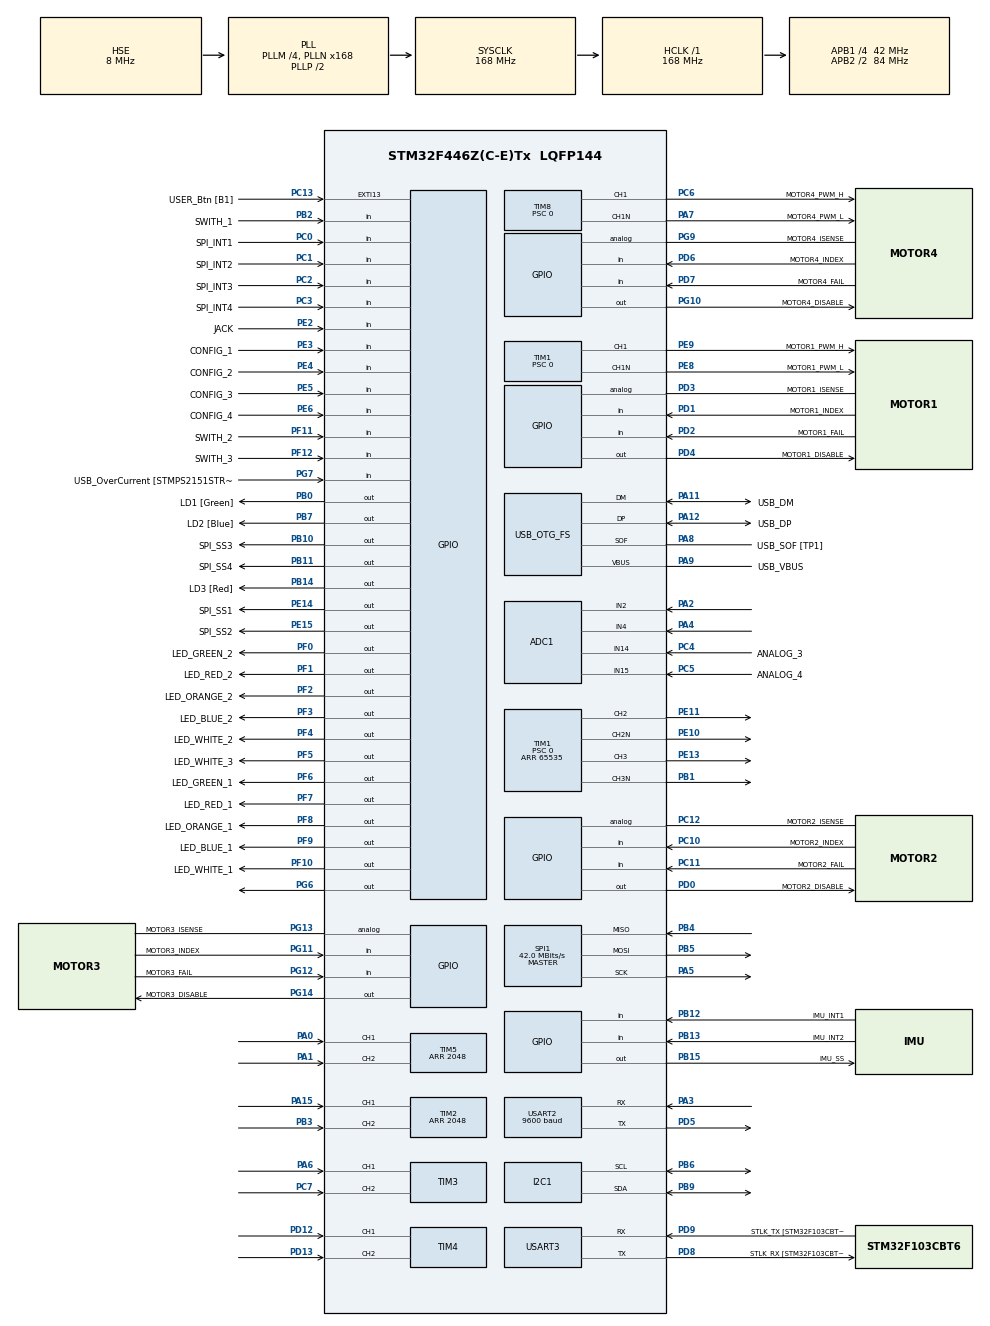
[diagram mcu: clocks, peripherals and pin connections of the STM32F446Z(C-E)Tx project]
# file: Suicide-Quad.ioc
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ADC1.Channel-2\#ChannelRegularConversion=ADC_CHANNEL_2
ADC1.NbrOfConversionFlag=1
ADC1.Rank-2\#ChannelRegularConversion=1
ADC1.SamplingTime-2\#ChannelRegularConversion=ADC_SAMPLETIME_3CYCLES
ADC1.master=1
Dma.Request0=USART2_TX
Dma.USART2_TX.0.Direction=DMA_MEMORY_TO_PERIPH
Dma.USART2_TX.0.FIFOMode=DMA_FIFOMODE_ENABLE
Dma.USART2_TX.0.FIFOThreshold=DMA_FIFO_THRESHOLD_FULL
Dma.USART2_TX.0.Instance=DMA1_Stream6
Dma.USART2_TX.0.MemBurst=DMA_MBURST_SINGLE
Dma.USART2_TX.0.MemDataAlignment=DMA_MDATAALIGN_BYTE
Dma.USART2_TX.0.MemInc=DMA_MINC_ENABLE
Dma.USART2_TX.0.Mode=DMA_CIRCULAR
Dma.USART2_TX.0.PeriphBurst=DMA_PBURST_SINGLE
Dma.USART2_TX.0.PeriphDataAlignment=DMA_PDATAALIGN_BYTE
Dma.USART2_TX.0.PeriphInc=DMA_PINC_DISABLE
Dma.USART2_TX.0.Priority=DMA_PRIORITY_LOW
Mcu.Family=STM32F4
Mcu.Name=STM32F446Z(C-E)Tx
Mcu.Package=LQFP144
NVIC.DMA1_Stream6_IRQn=true\:0\:0\:false\:false\:true\:false\:true\:true
NVIC.PriorityGroup=NVIC_PRIORITYGROUP_4
NVIC.TIM1_BRK_TIM9_IRQn=true\:0\:0\:false\:false\:true\:true\:true\:true
NVIC.USART2_IRQn=true\:0\:0\:false\:false\:true\:true\:true\:true
NVIC.USART3_IRQn=true\:0\:0\:false\:false\:true\:true\:true\:true
PA0-WKUP.Signal=S_TIM5_CH1
PA1.Signal=S_TIM5_CH2
PA10.GPIO_Label=USB_ID
PA10.Signal=USB_OTG_FS_ID
PA11.GPIO_Label=USB_DM
PA11.Mode=Device_Only
PA11.Signal=USB_OTG_FS_DM
PA12.GPIO_Label=USB_DP
PA12.Mode=Device_Only
PA12.Signal=USB_OTG_FS_DP
PA13.GPIO_Label=TMS
PA13.Mode=Serial_Wire
PA13.Signal=SYS_JTMS-SWDIO
PA14.GPIO_Label=TCK
PA14.Mode=Serial_Wire
PA14.Signal=SYS_JTCK-SWCLK
PA15.Signal=S_TIM2_CH1_ETR
PA2.Signal=ADCx_IN2
PA3.Mode=Asynchronous
PA3.Signal=USART2_RX
PA4.Signal=ADCx_IN4
PA5.Mode=Full_Duplex_Master
PA5.Signal=SPI1_SCK
PA6.Signal=S_TIM3_CH1
PA7.GPIO_Label=MOTOR4_PWM_L
PA7.Mode=PWM Generation1 CH1 CH1N
PA7.Signal=TIM8_CH1N
PA8.GPIO_Label=USB_SOF [TP1]
PA8.Mode=Activate_SOF_FS
PA8.Signal=USB_OTG_FS_SOF
PA9.GPIO_Label=USB_VBUS
PA9.Mode=Activate_VBUS
PA9.Signal=USB_OTG_FS_VBUS
PB0.GPIO_Label=LD1 [Green]
PB0.Signal=GPIO_Output
PB1.Mode=PWM Generation3 CH3 CH3N
PB1.Signal=TIM1_CH3N
PB10.GPIO_Label=SPI_SS3
PB10.Signal=GPIO_Output
PB11.GPIO_Label=SPI_SS4
PB11.Signal=GPIO_Output
PB12.GPIO_Label=IMU_INT1
PB12.Signal=GPIO_Input
PB13.GPIO_Label=IMU_INT2
PB13.Signal=GPIO_Input
PB14.GPIO_Label=LD3 [Red]
PB14.Signal=GPIO_Output
PB15.GPIO_Label=IMU_SS
PB15.Signal=GPIO_Output
PB2.GPIO_Label=SWITH_1
PB2.Signal=GPIO_Input
PB3.Signal=S_TIM2_CH2
PB4.Mode=Full_Duplex_Master
PB4.Signal=SPI1_MISO
PB5.Mode=Full_Duplex_Master
PB5.Signal=SPI1_MOSI
PB6.Mode=I2C
PB6.Signal=I2C1_SCL
PB7.GPIO_Label=LD2 [Blue]
PB7.Signal=GPIO_Output
PB9.Mode=I2C
PB9.Signal=I2C1_SDA
PC0.GPIO_Label=SPI_INT1
PC0.Signal=GPIO_Input
PC1.GPIO_Label=SPI_INT2
PC1.Signal=GPIO_Input
PC10.GPIO_Label=MOTOR2_INDEX
PC10.Signal=GPIO_Input
PC11.GPIO_Label=MOTOR2_FAIL
PC11.Signal=GPIO_Input
PC12.GPIO_Label=MOTOR2_ISENSE
PC12.Signal=GPIO_Analog
PC13.GPIO_Label=USER_Btn [B1]
PC13.Signal=GPXTI13
PC14-OSC32_IN.Mode=LSE-External-Oscillator
PC14-OSC32_IN.Signal=RCC_OSC32_IN
PC15-OSC32_OUT.Mode=LSE-External-Oscillator
PC15-OSC32_OUT.Signal=RCC_OSC32_OUT
PC2.GPIO_Label=SPI_INT3
PC2.Signal=GPIO_Input
PC3.GPIO_Label=SPI_INT4
PC3.Signal=GPIO_Input
PC4.GPIO_Label=ANALOG_3
PC4.Signal=ADCx_IN14
PC5.GPIO_Label=ANALOG_4
PC5.Signal=ADCx_IN15
PC6.GPIO_Label=MOTOR4_PWM_H
PC6.Signal=S_TIM8_CH1
PC7.Signal=S_TIM3_CH2
PD0.GPIO_Label=MOTOR2_DISABLE
PD0.Signal=GPIO_Output
PD1.GPIO_Label=MOTOR1_INDEX
PD1.Signal=GPIO_Input
PD12.Signal=S_TIM4_CH1
PD13.Signal=S_TIM4_CH2
PD2.GPIO_Label=MOTOR1_FAIL
PD2.Signal=GPIO_Input
PD3.GPIO_Label=MOTOR1_ISENSE
PD3.Signal=GPIO_Analog
PD4.GPIO_Label=MOTOR1_DISABLE
PD4.Signal=GPIO_Output
PD5.Mode=Asynchronous
PD5.Signal=USART2_TX
PD6.GPIO_Label=MOTOR4_INDEX
PD6.Signal=GPIO_Input
PD7.GPIO_Label=MOTOR4_FAIL
PD7.Signal=GPIO_Input
PD8.GPIO_Label=STLK_RX [STM32F103CBT6_PA3]
PD8.Mode=Asynchronous
PD8.Signal=USART3_TX
PD9.GPIO_Label=STLK_TX [STM32F103CBT6_PA2]
PD9.Mode=Asynchronous
PD9.Signal=USART3_RX
PE10.Mode=PWM Generation2 CH2 CH2N
PE10.Signal=TIM1_CH2N
PE11.Signal=S_TIM1_CH2
PE13.Signal=S_TIM1_CH3
PE14.GPIO_Label=SPI_SS1
PE14.Signal=GPIO_Output
PE15.GPIO_Label=SPI_SS2
PE15.Signal=GPIO_Output
PE2.GPIO_Label=JACK
PE2.Signal=GPIO_Input
PE3.GPIO_Label=CONFIG_1
PE3.Signal=GPIO_Input
PE4.GPIO_Label=CONFIG_2
PE4.Signal=GPIO_Input
PE5.GPIO_Label=CONFIG_3
PE5.Signal=GPIO_Input
PE6.GPIO_Label=CONFIG_4
PE6.Signal=GPIO_Input
PE8.GPIO_Label=MOTOR1_PWM_L
PE8.Mode=PWM Generation1 CH1 CH1N
PE8.Signal=TIM1_CH1N
PE9.GPIO_Label=MOTOR1_PWM_H
PE9.Signal=S_TIM1_CH1
PF0.GPIO_Label=LED_GREEN_2
PF0.Signal=GPIO_Output
PF1.GPIO_Label=LED_RED_2
PF1.Signal=GPIO_Output
PF10.GPIO_Label=LED_WHITE_1
PF10.Signal=GPIO_Output
PF11.GPIO_Label=SWITH_2
PF11.Signal=GPIO_Input
PF12.GPIO_Label=SWITH_3
PF12.Signal=GPIO_Input
PF2.GPIO_Label=LED_ORANGE_2
PF2.Signal=GPIO_Output
PF3.GPIO_Label=LED_BLUE_2
PF3.Signal=GPIO_Output
PF4.GPIO_Label=LED_WHITE_2
PF4.Signal=GPIO_Output
PF5.GPIO_Label=LED_WHITE_3
PF5.Signal=GPIO_Output
PF6.GPIO_Label=LED_GREEN_1
PF6.Signal=GPIO_Output
PF7.GPIO_Label=LED_RED_1
PF7.Signal=GPIO_Output
PF8.GPIO_Label=LED_ORANGE_1
PF8.Signal=GPIO_Output
PF9.GPIO_Label=LED_BLUE_1
PF9.Signal=GPIO_Output
PG10.GPIO_Label=MOTOR4_DISABLE
PG10.Signal=GPIO_Output
PG11.GPIO_Label=MOTOR3_INDEX
PG11.Signal=GPIO_Input
PG12.GPIO_Label=MOTOR3_FAIL
PG12.Signal=GPIO_Input
PG13.GPIO_Label=MOTOR3_ISENSE
PG13.Signal=GPIO_Analog
PG14.GPIO_Label=MOTOR3_DISABLE
PG14.Signal=GPIO_Output
PG6.Signal=GPIO_Output
PG7.GPIO_Label=USB_OverCurrent [STMPS2151STR_FAULT]
PG7.Signal=GPIO_Input
PG9.GPIO_Label=MOTOR4_ISENSE
PG9.Signal=GPIO_Analog
PH0-OSC_IN.GPIO_Label=MCO [STM32F103CBT6_PA8]
PH0-OSC_IN.Mode=HSE-External-Clock-Source
PH0-OSC_IN.Signal=RCC_OSC_IN
PH1-OSC_OUT.Mode=HSE-External-Clock-Source
PH1-OSC_OUT.Signal=RCC_OSC_OUT
ProjectManager.HeapSize=0x200
ProjectManager.StackSize=0x400
ProjectManager.TargetToolchain=Makefile
RCC.48MHZClocksFreq_Value=24000000
RCC.AHBFreq_Value=168000000
RCC.APB1CLKDivider=RCC_HCLK_DIV4
RCC.APB1Freq_Value=42000000
RCC.APB1TimFreq_Value=84000000
RCC.APB2CLKDivider=RCC_HCLK_DIV2
RCC.APB2Freq_Value=84000000
RCC.APB2TimFreq_Value=168000000
RCC.CortexFreq_Value=168000000
RCC.HCLKFreq_Value=168000000
RCC.HSE_VALUE=8000000
RCC.HSI_VALUE=16000000
RCC.PLLM=4
RCC.PLLMUL=RCC_PLL_MUL9
RCC.PLLN=168
RCC.PLLQ=7
RCC.PRESCALERUSB=RCC_USBCLKSOURCE_PLL_DIV1_5
RCC.SYSCLKFreq_VALUE=168000000
RCC.SYSCLKSource=RCC_SYSCLKSOURCE_PLLCLK
RCC.SYSCLKSourceVirtual=RCC_SYSCLKSOURCE_PLLCLK
RCC.USBFreq_Value=48000000
RCC.VCOOutputFreq_Value=336000000
SH.ADCx_IN14.0=ADC1_IN14,IN14
SH.ADCx_IN15.0=ADC1_IN15,IN15
SH.ADCx_IN2.0=ADC1_IN2,IN2
SH.ADCx_IN4.0=ADC1_IN4,IN4
SH.S_TIM1_CH1.0=TIM1_CH1,PWM Generation1 CH1 CH1N
SH.S_TIM1_CH2.0=TIM1_CH2,PWM Generation2 CH2 CH2N
SH.S_TIM1_CH3.0=TIM1_CH3,PWM Generation3 CH3 CH3N
SH.S_TIM2_CH1_ETR.0=TIM2_CH1,Encoder_Interface
SH.S_TIM2_CH2.0=TIM2_CH2,Encoder_Interface
SH.S_TIM3_CH1.0=TIM3_CH1,Encoder_Interface
SH.S_TIM3_CH2.0=TIM3_CH2,Encoder_Interface
SH.S_TIM4_CH1.0=TIM4_CH1,Encoder_Interface
SH.S_TIM4_CH2.0=TIM4_CH2,Encoder_Interface
SH.S_TIM5_CH1.0=TIM5_CH1,Encoder_Interface
SH.S_TIM5_CH2.0=TIM5_CH2,Encoder_Interface
SH.S_TIM8_CH1.0=TIM8_CH1,PWM Generation1 CH1 CH1N
SPI1.CalculateBaudRate=42.0 MBits/s
SPI1.Direction=SPI_DIRECTION_2LINES
SPI1.Mode=SPI_MODE_MASTER
SPI1.VirtualType=VM_MASTER
TIM1.Channel-PWM\ Generation1\ CH1\ CH1N=TIM_CHANNEL_1
TIM1.Channel-PWM\ Generation2\ CH2\ CH2N=TIM_CHANNEL_2
TIM1.Channel-PWM\ Generation3\ CH3\ CH3N=TIM_CHANNEL_3
TIM1.Period=65535
TIM1.Prescaler=0
TIM1.Pulse-PWM\ Generation1\ CH1\ CH1N=250
TIM2.AutoReloadPreload=TIM_AUTORELOAD_PRELOAD_ENABLE
TIM2.EncoderMode=TIM_ENCODERMODE_TI1
TIM2.IC1Filter=0
TIM2.IC2Filter=0
TIM2.Period=2048
TIM5.AutoReloadPreload=TIM_AUTORELOAD_PRELOAD_ENABLE
TIM5.EncoderMode=TIM_ENCODERMODE_TI1
TIM5.IC1Filter=0
TIM5.IC2Filter=0
TIM5.Period=2048
TIM8.Channel-PWM\ Generation1\ CH1\ CH1N=TIM_CHANNEL_1
TIM8.Period=65535
TIM8.Prescaler=0
TIM8.Pulse-PWM\ Generation1\ CH1\ CH1N=0
USART2.BaudRate=9600
USART2.Mode=MODE_TX_RX
USART2.VirtualMode=VM_ASYNC
USART3.VirtualMode=VM_ASYNC
USB_OTG_FS.VirtualMode=Device_Only
VP_TIM1_VS_ClockSourceINT.Mode=Internal
VP_TIM8_VS_ClockSourceINT.Mode=Internal
VP_TIM9_VS_ClockSourceINT.Mode=Internal
board=NUCLEO-F446ZE

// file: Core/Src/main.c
/* USER CODE BEGIN Header */
/**
 ******************************************************************************
 * @file           : main.c
 * @brief          : Main program body
 ******************************************************************************
 * @attention
 *
 * Copyright (c) 2023 STMicroelectronics.
 * All rights reserved.
 *
 * This software is licensed under terms that can be found in the LICENSE file
 * in the root directory of this software component.
 * If no LICENSE file comes with this software, it is provided AS-IS.
 *
 ******************************************************************************
 */
/* USER CODE END Header */
#include "main.h"

/* USER CODE BEGIN Includes */
#include <math.h>
#include "main.h"
#include "string.h"
#include "utils.h"
#include "encoder.h"
#include "pwm.h"
#include "odometer.h"
#include "Message/send.h"
#include "Message/generator.h"
#include "servo.h"
#include "position.h"
#include "map.h"

/* USER CODE END Includes */

ADC_HandleTypeDef hadc1;

I2C_HandleTypeDef hi2c1;

SPI_HandleTypeDef hspi1;

TIM_HandleTypeDef htim1;
TIM_HandleTypeDef htim2;
TIM_HandleTypeDef htim3;
TIM_HandleTypeDef htim4;
TIM_HandleTypeDef htim5;
TIM_HandleTypeDef htim8;
TIM_HandleTypeDef htim9;

UART_HandleTypeDef huart2;
UART_HandleTypeDef huart3;
DMA_HandleTypeDef hdma_usart2_tx;

PCD_HandleTypeDef hpcd_USB_OTG_FS;

void SystemClock_Config(void);
static void MX_GPIO_Init(void);
static void MX_DMA_Init(void);
static void MX_I2C1_Init(void);
static void MX_TIM1_Init(void);
static void MX_TIM2_Init(void);
static void MX_TIM3_Init(void);
static void MX_TIM4_Init(void);
static void MX_TIM5_Init(void);
static void MX_TIM8_Init(void);
static void MX_USART2_UART_Init(void);
static void MX_USART3_UART_Init(void);
static void MX_USB_OTG_FS_PCD_Init(void);
static void MX_ADC1_Init(void);
static void MX_SPI1_Init(void);
static void MX_TIM9_Init(void);

/* USER CODE BEGIN 0 */

/*
 * The Callback function
 */
uint8_t buff [500];
void HAL_TIM_PeriodElapsedCallback(TIM_HandleTypeDef* htim)
{
    if (htim == &htim9)
    {
        applyGhostMouvement();
    }
}

uint8_t idArUco;

void SwitchId(uint8_t id)
{
    idArUco = id;
}

/* USER CODE END 0 */

int main(void)
{

  /* MCU Configuration--------------------------------------------------------*/

  /* Reset of all peripherals, Initializes the Flash interface and the Systick. */
  HAL_Init();

  /* Configure the system clock */
  SystemClock_Config();

  /* Initialize all configured peripherals */
  MX_GPIO_Init();
  MX_DMA_Init();
  MX_I2C1_Init();
  MX_TIM1_Init();
  MX_TIM2_Init();
  MX_TIM3_Init();
  MX_TIM4_Init();
  MX_TIM5_Init();
  MX_TIM8_Init();
  MX_USART2_UART_Init();
  MX_USART3_UART_Init();
  MX_USB_OTG_FS_PCD_Init();
  MX_ADC1_Init();
  MX_SPI1_Init();
  MX_TIM9_Init();
  /* USER CODE BEGIN 2 */
  initCommunication(&huart2,&huart3);
  initEncoder(&htim5, &htim2);
  initPWM(&htim8, &htim1);
  //initDMA(&huart2);
  initServo();
  setPWM(RIGHT,0);
  setPWM(LEFT,0);
  //uint64_t millis = HAL_GetTick();
  //uint64_t current;*/
  /* USER CODE END 2 */

  /* Infinite loop */
  /* USER CODE BEGIN WHILE */
  /*
  while (getId() == 255)

  {
      sendAskPosition();
      receiveRequest();
  }
    */
  while (1)
  {
      sendDebugDouble(5.6,'y');
      sendDebugPosition(5.6,654.5,'t');
      sendDebugInt(5,'r');
  }
  /*
     int id = getId();
     while (id > 42){
  // on veut la bonne position
  sendAskPosition();
  id = getId();
  }
  init_map(id);
  /// TODO aller sur le centre
  struct intResult result = get_father();
  uint8_t nbrmvt = result.nbrmvt;
  uint8_t orientation = result.orientation;
  uint8_t oldorientation = orientation;
  struct PositionCommand position = getPositionArUco();
  Location current = {0, 0, oldorientation};
  Location destination = {position.x, position.y, oldorientation};
  int mvt = initMouvement(current, destination);
  while (1)
  {
  mvt = getState();
  if (mvt == 1)
  {
  current = {0, 0, oldorientation};
  destination = {nbrmvt, nbrmvt, orientation};
  mvt = initMouvement(current, destination);

  result = get_father();
  nbrmvt = result.nbrmvt;
  oldorientation = orientation;
  orientation = result.orientation;

  }*/
    /* USER CODE END WHILE */

    /* USER CODE BEGIN 3 */
  //}

  /* USER CODE END 3 */
}

void SystemClock_Config(void)
{
  RCC_OscInitTypeDef RCC_OscInitStruct = {0};
  RCC_ClkInitTypeDef RCC_ClkInitStruct = {0};

  /** Configure the main internal regulator output voltage
  */
  __HAL_RCC_PWR_CLK_ENABLE();
  __HAL_PWR_VOLTAGESCALING_CONFIG(PWR_REGULATOR_VOLTAGE_SCALE1);

  /** Initializes the RCC Oscillators according to the specified parameters
  * in the RCC_OscInitTypeDef structure.
  */
  RCC_OscInitStruct.OscillatorType = RCC_OSCILLATORTYPE_HSE;
  RCC_OscInitStruct.HSEState = RCC_HSE_BYPASS;
  RCC_OscInitStruct.PLL.PLLState = RCC_PLL_ON;
  RCC_OscInitStruct.PLL.PLLSource = RCC_PLLSOURCE_HSE;
  RCC_OscInitStruct.PLL.PLLM = 4;
  RCC_OscInitStruct.PLL.PLLN = 168;
  RCC_OscInitStruct.PLL.PLLP = RCC_PLLP_DIV2;
  RCC_OscInitStruct.PLL.PLLQ = 7;
  RCC_OscInitStruct.PLL.PLLR = 2;
  if (HAL_RCC_OscConfig(&RCC_OscInitStruct) != HAL_OK)
  {
    Error_Handler();
  }

  /** Initializes the CPU, AHB and APB buses clocks
  */
  RCC_ClkInitStruct.ClockType = RCC_CLOCKTYPE_HCLK|RCC_CLOCKTYPE_SYSCLK
                              |RCC_CLOCKTYPE_PCLK1|RCC_CLOCKTYPE_PCLK2;
  RCC_ClkInitStruct.SYSCLKSource = RCC_SYSCLKSOURCE_PLLCLK;
  RCC_ClkInitStruct.AHBCLKDivider = RCC_SYSCLK_DIV1;
  RCC_ClkInitStruct.APB1CLKDivider = RCC_HCLK_DIV4;
  RCC_ClkInitStruct.APB2CLKDivider = RCC_HCLK_DIV2;

  if (HAL_RCC_ClockConfig(&RCC_ClkInitStruct, FLASH_LATENCY_5) != HAL_OK)
  {
    Error_Handler();
  }
}

static void MX_ADC1_Init(void)
{

  ADC_ChannelConfTypeDef sConfig = {0};

  /** Configure the global features of the ADC (Clock, Resolution, Data Alignment and number of conversion)
  */
  hadc1.Instance = ADC1;
  hadc1.Init.ClockPrescaler = ADC_CLOCK_SYNC_PCLK_DIV4;
  hadc1.Init.Resolution = ADC_RESOLUTION_12B;
  hadc1.Init.ScanConvMode = DISABLE;
  hadc1.Init.ContinuousConvMode = DISABLE;
  hadc1.Init.DiscontinuousConvMode = DISABLE;
  hadc1.Init.ExternalTrigConvEdge = ADC_EXTERNALTRIGCONVEDGE_NONE;
  hadc1.Init.ExternalTrigConv = ADC_SOFTWARE_START;
  hadc1.Init.DataAlign = ADC_DATAALIGN_RIGHT;
  hadc1.Init.NbrOfConversion = 1;
  hadc1.Init.DMAContinuousRequests = DISABLE;
  hadc1.Init.EOCSelection = ADC_EOC_SINGLE_CONV;
  if (HAL_ADC_Init(&hadc1) != HAL_OK)
  {
    Error_Handler();
  }

  /** Configure for the selected ADC regular channel its corresponding rank in the sequencer and its sample time.
  */
  sConfig.Channel = ADC_CHANNEL_2;
  sConfig.Rank = 1;
  sConfig.SamplingTime = ADC_SAMPLETIME_3CYCLES;
  if (HAL_ADC_ConfigChannel(&hadc1, &sConfig) != HAL_OK)
  {
    Error_Handler();
  }

}

static void MX_I2C1_Init(void)
{

  hi2c1.Instance = I2C1;
  hi2c1.Init.ClockSpeed = 100000;
  hi2c1.Init.DutyCycle = I2C_DUTYCYCLE_2;
  hi2c1.Init.OwnAddress1 = 0;
  hi2c1.Init.AddressingMode = I2C_ADDRESSINGMODE_7BIT;
  hi2c1.Init.DualAddressMode = I2C_DUALADDRESS_DISABLE;
  hi2c1.Init.OwnAddress2 = 0;
  hi2c1.Init.GeneralCallMode = I2C_GENERALCALL_DISABLE;
  hi2c1.Init.NoStretchMode = I2C_NOSTRETCH_DISABLE;
  if (HAL_I2C_Init(&hi2c1) != HAL_OK)
  {
    Error_Handler();
  }

}

static void MX_SPI1_Init(void)
{

  /* SPI1 parameter configuration*/
  hspi1.Instance = SPI1;
  hspi1.Init.Mode = SPI_MODE_MASTER;
  hspi1.Init.Direction = SPI_DIRECTION_2LINES;
  hspi1.Init.DataSize = SPI_DATASIZE_8BIT;
  hspi1.Init.CLKPolarity = SPI_POLARITY_LOW;
  hspi1.Init.CLKPhase = SPI_PHASE_1EDGE;
  hspi1.Init.NSS = SPI_NSS_SOFT;
  hspi1.Init.BaudRatePrescaler = SPI_BAUDRATEPRESCALER_2;
  hspi1.Init.FirstBit = SPI_FIRSTBIT_MSB;
  hspi1.Init.TIMode = SPI_TIMODE_DISABLE;
  hspi1.Init.CRCCalculation = SPI_CRCCALCULATION_DISABLE;
  hspi1.Init.CRCPolynomial = 10;
  if (HAL_SPI_Init(&hspi1) != HAL_OK)
  {
    Error_Handler();
  }

}

static void MX_TIM1_Init(void)
{

  TIM_ClockConfigTypeDef sClockSourceConfig = {0};
  TIM_MasterConfigTypeDef sMasterConfig = {0};
  TIM_OC_InitTypeDef sConfigOC = {0};
  TIM_BreakDeadTimeConfigTypeDef sBreakDeadTimeConfig = {0};

  htim1.Instance = TIM1;
  htim1.Init.Prescaler = 0;
  htim1.Init.CounterMode = TIM_COUNTERMODE_UP;
  htim1.Init.Period = 65535;
  htim1.Init.ClockDivision = TIM_CLOCKDIVISION_DIV1;
  htim1.Init.RepetitionCounter = 0;
  htim1.Init.AutoReloadPreload = TIM_AUTORELOAD_PRELOAD_DISABLE;
  if (HAL_TIM_Base_Init(&htim1) != HAL_OK)
  {
    Error_Handler();
  }
  sClockSourceConfig.ClockSource = TIM_CLOCKSOURCE_INTERNAL;
  if (HAL_TIM_ConfigClockSource(&htim1, &sClockSourceConfig) != HAL_OK)
  {
    Error_Handler();
  }
  if (HAL_TIM_PWM_Init(&htim1) != HAL_OK)
  {
    Error_Handler();
  }
  sMasterConfig.MasterOutputTrigger = TIM_TRGO_RESET;
  sMasterConfig.MasterSlaveMode = TIM_MASTERSLAVEMODE_DISABLE;
  if (HAL_TIMEx_MasterConfigSynchronization(&htim1, &sMasterConfig) != HAL_OK)
  {
    Error_Handler();
  }
  sConfigOC.OCMode = TIM_OCMODE_PWM1;
  sConfigOC.Pulse = 250;
  sConfigOC.OCPolarity = TIM_OCPOLARITY_HIGH;
  sConfigOC.OCNPolarity = TIM_OCNPOLARITY_HIGH;
  sConfigOC.OCFastMode = TIM_OCFAST_DISABLE;
  sConfigOC.OCIdleState = TIM_OCIDLESTATE_RESET;
  sConfigOC.OCNIdleState = TIM_OCNIDLESTATE_RESET;
  if (HAL_TIM_PWM_ConfigChannel(&htim1, &sConfigOC, TIM_CHANNEL_1) != HAL_OK)
  {
    Error_Handler();
  }
  sConfigOC.Pulse = 0;
  if (HAL_TIM_PWM_ConfigChannel(&htim1, &sConfigOC, TIM_CHANNEL_2) != HAL_OK)
  {
    Error_Handler();
  }
  if (HAL_TIM_PWM_ConfigChannel(&htim1, &sConfigOC, TIM_CHANNEL_3) != HAL_OK)
  {
    Error_Handler();
  }
  sBreakDeadTimeConfig.OffStateRunMode = TIM_OSSR_DISABLE;
  sBreakDeadTimeConfig.OffStateIDLEMode = TIM_OSSI_DISABLE;
  sBreakDeadTimeConfig.LockLevel = TIM_LOCKLEVEL_OFF;
  sBreakDeadTimeConfig.DeadTime = 0;
  sBreakDeadTimeConfig.BreakState = TIM_BREAK_DISABLE;
  sBreakDeadTimeConfig.BreakPolarity = TIM_BREAKPOLARITY_HIGH;
  sBreakDeadTimeConfig.AutomaticOutput = TIM_AUTOMATICOUTPUT_DISABLE;
  if (HAL_TIMEx_ConfigBreakDeadTime(&htim1, &sBreakDeadTimeConfig) != HAL_OK)
  {
    Error_Handler();
  }
  HAL_TIM_MspPostInit(&htim1);

}

static void MX_TIM2_Init(void)
{

  TIM_Encoder_InitTypeDef sConfig = {0};
  TIM_MasterConfigTypeDef sMasterConfig = {0};

  htim2.Instance = TIM2;
  htim2.Init.Prescaler = 0;
  htim2.Init.CounterMode = TIM_COUNTERMODE_UP;
  htim2.Init.Period = 2048;
  htim2.Init.ClockDivision = TIM_CLOCKDIVISION_DIV1;
  htim2.Init.AutoReloadPreload = TIM_AUTORELOAD_PRELOAD_ENABLE;
  sConfig.EncoderMode = TIM_ENCODERMODE_TI1;
  sConfig.IC1Polarity = TIM_ICPOLARITY_RISING;
  sConfig.IC1Selection = TIM_ICSELECTION_DIRECTTI;
  sConfig.IC1Prescaler = TIM_ICPSC_DIV1;
  sConfig.IC1Filter = 0;
  sConfig.IC2Polarity = TIM_ICPOLARITY_RISING;
  sConfig.IC2Selection = TIM_ICSELECTION_DIRECTTI;
  sConfig.IC2Prescaler = TIM_ICPSC_DIV1;
  sConfig.IC2Filter = 0;
  if (HAL_TIM_Encoder_Init(&htim2, &sConfig) != HAL_OK)
  {
    Error_Handler();
  }
  sMasterConfig.MasterOutputTrigger = TIM_TRGO_RESET;
  sMasterConfig.MasterSlaveMode = TIM_MASTERSLAVEMODE_DISABLE;
  if (HAL_TIMEx_MasterConfigSynchronization(&htim2, &sMasterConfig) != HAL_OK)
  {
    Error_Handler();
  }

}

static void MX_TIM3_Init(void)
{

  TIM_Encoder_InitTypeDef sConfig = {0};
  TIM_MasterConfigTypeDef sMasterConfig = {0};

  htim3.Instance = TIM3;
  htim3.Init.Prescaler = 0;
  htim3.Init.CounterMode = TIM_COUNTERMODE_UP;
  htim3.Init.Period = 65535;
  htim3.Init.ClockDivision = TIM_CLOCKDIVISION_DIV1;
  htim3.Init.AutoReloadPreload = TIM_AUTORELOAD_PRELOAD_DISABLE;
  sConfig.EncoderMode = TIM_ENCODERMODE_TI1;
  sConfig.IC1Polarity = TIM_ICPOLARITY_RISING;
  sConfig.IC1Selection = TIM_ICSELECTION_DIRECTTI;
  sConfig.IC1Prescaler = TIM_ICPSC_DIV1;
  sConfig.IC1Filter = 0;
  sConfig.IC2Polarity = TIM_ICPOLARITY_RISING;
  sConfig.IC2Selection = TIM_ICSELECTION_DIRECTTI;
  sConfig.IC2Prescaler = TIM_ICPSC_DIV1;
  sConfig.IC2Filter = 0;
  if (HAL_TIM_Encoder_Init(&htim3, &sConfig) != HAL_OK)
  {
    Error_Handler();
  }
  sMasterConfig.MasterOutputTrigger = TIM_TRGO_RESET;
  sMasterConfig.MasterSlaveMode = TIM_MASTERSLAVEMODE_DISABLE;
  if (HAL_TIMEx_MasterConfigSynchronization(&htim3, &sMasterConfig) != HAL_OK)
  {
    Error_Handler();
  }

}

static void MX_TIM4_Init(void)
{

  TIM_Encoder_InitTypeDef sConfig = {0};
  TIM_MasterConfigTypeDef sMasterConfig = {0};

  htim4.Instance = TIM4;
  htim4.Init.Prescaler = 0;
  htim4.Init.CounterMode = TIM_COUNTERMODE_UP;
  htim4.Init.Period = 65535;
  htim4.Init.ClockDivision = TIM_CLOCKDIVISION_DIV1;
  htim4.Init.AutoReloadPreload = TIM_AUTORELOAD_PRELOAD_DISABLE;
  sConfig.EncoderMode = TIM_ENCODERMODE_TI1;
  sConfig.IC1Polarity = TIM_ICPOLARITY_RISING;
  sConfig.IC1Selection = TIM_ICSELECTION_DIRECTTI;
  sConfig.IC1Prescaler = TIM_ICPSC_DIV1;
  sConfig.IC1Filter = 0;
  sConfig.IC2Polarity = TIM_ICPOLARITY_RISING;
  sConfig.IC2Selection = TIM_ICSELECTION_DIRECTTI;
  sConfig.IC2Prescaler = TIM_ICPSC_DIV1;
  sConfig.IC2Filter = 0;
  if (HAL_TIM_Encoder_Init(&htim4, &sConfig) != HAL_OK)
  {
    Error_Handler();
  }
  sMasterConfig.MasterOutputTrigger = TIM_TRGO_RESET;
  sMasterConfig.MasterSlaveMode = TIM_MASTERSLAVEMODE_DISABLE;
  if (HAL_TIMEx_MasterConfigSynchronization(&htim4, &sMasterConfig) != HAL_OK)
  {
    Error_Handler();
  }

}

static void MX_TIM5_Init(void)
{

  TIM_Encoder_InitTypeDef sConfig = {0};
  TIM_MasterConfigTypeDef sMasterConfig = {0};

  htim5.Instance = TIM5;
  htim5.Init.Prescaler = 0;
  htim5.Init.CounterMode = TIM_COUNTERMODE_UP;
  htim5.Init.Period = 2048;
  htim5.Init.ClockDivision = TIM_CLOCKDIVISION_DIV1;
  htim5.Init.AutoReloadPreload = TIM_AUTORELOAD_PRELOAD_ENABLE;
  sConfig.EncoderMode = TIM_ENCODERMODE_TI1;
  sConfig.IC1Polarity = TIM_ICPOLARITY_RISING;
  sConfig.IC1Selection = TIM_ICSELECTION_DIRECTTI;
  sConfig.IC1Prescaler = TIM_ICPSC_DIV1;
  sConfig.IC1Filter = 0;
  sConfig.IC2Polarity = TIM_ICPOLARITY_RISING;
  sConfig.IC2Selection = TIM_ICSELECTION_DIRECTTI;
  sConfig.IC2Prescaler = TIM_ICPSC_DIV1;
  sConfig.IC2Filter = 0;
  if (HAL_TIM_Encoder_Init(&htim5, &sConfig) != HAL_OK)
  {
    Error_Handler();
  }
  sMasterConfig.MasterOutputTrigger = TIM_TRGO_RESET;
  sMasterConfig.MasterSlaveMode = TIM_MASTERSLAVEMODE_DISABLE;
  if (HAL_TIMEx_MasterConfigSynchronization(&htim5, &sMasterConfig) != HAL_OK)
  {
    Error_Handler();
  }

}

static void MX_TIM8_Init(void)
{

  TIM_ClockConfigTypeDef sClockSourceConfig = {0};
  TIM_MasterConfigTypeDef sMasterConfig = {0};
  TIM_OC_InitTypeDef sConfigOC = {0};
  TIM_BreakDeadTimeConfigTypeDef sBreakDeadTimeConfig = {0};

  htim8.Instance = TIM8;
  htim8.Init.Prescaler = 0;
  htim8.Init.CounterMode = TIM_COUNTERMODE_UP;
  htim8.Init.Period = 65535;
  htim8.Init.ClockDivision = TIM_CLOCKDIVISION_DIV1;
  htim8.Init.RepetitionCounter = 0;
  htim8.Init.AutoReloadPreload = TIM_AUTORELOAD_PRELOAD_DISABLE;
  if (HAL_TIM_Base_Init(&htim8) != HAL_OK)
  {
    Error_Handler();
  }
  sClockSourceConfig.ClockSource = TIM_CLOCKSOURCE_INTERNAL;
  if (HAL_TIM_ConfigClockSource(&htim8, &sClockSourceConfig) != HAL_OK)
  {
    Error_Handler();
  }
  if (HAL_TIM_PWM_Init(&htim8) != HAL_OK)
  {
    Error_Handler();
  }
  sMasterConfig.MasterOutputTrigger = TIM_TRGO_RESET;
  sMasterConfig.MasterSlaveMode = TIM_MASTERSLAVEMODE_DISABLE;
  if (HAL_TIMEx_MasterConfigSynchronization(&htim8, &sMasterConfig) != HAL_OK)
  {
    Error_Handler();
  }
  sConfigOC.OCMode = TIM_OCMODE_PWM1;
  sConfigOC.Pulse = 0;
  sConfigOC.OCPolarity = TIM_OCPOLARITY_HIGH;
  sConfigOC.OCNPolarity = TIM_OCNPOLARITY_HIGH;
  sConfigOC.OCFastMode = TIM_OCFAST_DISABLE;
  sConfigOC.OCIdleState = TIM_OCIDLESTATE_RESET;
  sConfigOC.OCNIdleState = TIM_OCNIDLESTATE_RESET;
  if (HAL_TIM_PWM_ConfigChannel(&htim8, &sConfigOC, TIM_CHANNEL_1) != HAL_OK)
  {
    Error_Handler();
  }
  sBreakDeadTimeConfig.OffStateRunMode = TIM_OSSR_DISABLE;
  sBreakDeadTimeConfig.OffStateIDLEMode = TIM_OSSI_DISABLE;
  sBreakDeadTimeConfig.LockLevel = TIM_LOCKLEVEL_OFF;
  sBreakDeadTimeConfig.DeadTime = 0;
  sBreakDeadTimeConfig.BreakState = TIM_BREAK_DISABLE;
  sBreakDeadTimeConfig.BreakPolarity = TIM_BREAKPOLARITY_HIGH;
  sBreakDeadTimeConfig.AutomaticOutput = TIM_AUTOMATICOUTPUT_DISABLE;
  if (HAL_TIMEx_ConfigBreakDeadTime(&htim8, &sBreakDeadTimeConfig) != HAL_OK)
  {
    Error_Handler();
  }
  HAL_TIM_MspPostInit(&htim8);

}

static void MX_TIM9_Init(void)
{

  TIM_ClockConfigTypeDef sClockSourceConfig = {0};

  htim9.Instance = TIM9;
  htim9.Init.Prescaler = 0;
  htim9.Init.CounterMode = TIM_COUNTERMODE_UP;
  htim9.Init.Period = 65535;
  htim9.Init.ClockDivision = TIM_CLOCKDIVISION_DIV1;
  htim9.Init.AutoReloadPreload = TIM_AUTORELOAD_PRELOAD_DISABLE;
  if (HAL_TIM_Base_Init(&htim9) != HAL_OK)
  {
    Error_Handler();
  }
  sClockSourceConfig.ClockSource = TIM_CLOCKSOURCE_INTERNAL;
  if (HAL_TIM_ConfigClockSource(&htim9, &sClockSourceConfig) != HAL_OK)
  {
    Error_Handler();
  }

}

static void MX_USART2_UART_Init(void)
{

  huart2.Instance = USART2;
  huart2.Init.BaudRate = 9600;
  huart2.Init.WordLength = UART_WORDLENGTH_8B;
  huart2.Init.StopBits = UART_STOPBITS_1;
  huart2.Init.Parity = UART_PARITY_NONE;
  huart2.Init.Mode = UART_MODE_TX_RX;
  huart2.Init.HwFlowCtl = UART_HWCONTROL_NONE;
  huart2.Init.OverSampling = UART_OVERSAMPLING_16;
  if (HAL_UART_Init(&huart2) != HAL_OK)
  {
    Error_Handler();
  }

}

static void MX_USART3_UART_Init(void)
{

  huart3.Instance = USART3;
  huart3.Init.BaudRate = 115200;
  huart3.Init.WordLength = UART_WORDLENGTH_8B;
  huart3.Init.StopBits = UART_STOPBITS_1;
  huart3.Init.Parity = UART_PARITY_NONE;
  huart3.Init.Mode = UART_MODE_TX_RX;
  huart3.Init.HwFlowCtl = UART_HWCONTROL_NONE;
  huart3.Init.OverSampling = UART_OVERSAMPLING_16;
  if (HAL_UART_Init(&huart3) != HAL_OK)
  {
    Error_Handler();
  }

}

static void MX_USB_OTG_FS_PCD_Init(void)
{

  hpcd_USB_OTG_FS.Instance = USB_OTG_FS;
  hpcd_USB_OTG_FS.Init.dev_endpoints = 6;
  hpcd_USB_OTG_FS.Init.speed = PCD_SPEED_FULL;
  hpcd_USB_OTG_FS.Init.dma_enable = DISABLE;
  hpcd_USB_OTG_FS.Init.phy_itface = PCD_PHY_EMBEDDED;
  hpcd_USB_OTG_FS.Init.Sof_enable = ENABLE;
  hpcd_USB_OTG_FS.Init.low_power_enable = DISABLE;
  hpcd_USB_OTG_FS.Init.lpm_enable = DISABLE;
  hpcd_USB_OTG_FS.Init.vbus_sensing_enable = ENABLE;
  hpcd_USB_OTG_FS.Init.use_dedicated_ep1 = DISABLE;
  if (HAL_PCD_Init(&hpcd_USB_OTG_FS) != HAL_OK)
  {
    Error_Handler();
  }

}

static void MX_DMA_Init(void)
{

  /* DMA controller clock enable */
  __HAL_RCC_DMA1_CLK_ENABLE();

  /* DMA interrupt init */
  /* DMA1_Stream6_IRQn interrupt configuration */
  HAL_NVIC_SetPriority(DMA1_Stream6_IRQn, 0, 0);
  HAL_NVIC_EnableIRQ(DMA1_Stream6_IRQn);

}

static void MX_GPIO_Init(void)
{
  GPIO_InitTypeDef GPIO_InitStruct = {0};

  /* GPIO Ports Clock Enable */
  __HAL_RCC_GPIOE_CLK_ENABLE();
  __HAL_RCC_GPIOC_CLK_ENABLE();
  __HAL_RCC_GPIOF_CLK_ENABLE();
  __HAL_RCC_GPIOH_CLK_ENABLE();
  __HAL_RCC_GPIOA_CLK_ENABLE();
  __HAL_RCC_GPIOB_CLK_ENABLE();
  __HAL_RCC_GPIOD_CLK_ENABLE();
  __HAL_RCC_GPIOG_CLK_ENABLE();

  /*Configure GPIO pin Output Level */
  HAL_GPIO_WritePin(GPIOF, LED_GREEN_2_Pin|LED_RED_2_Pin|LED_ORANGE_2_Pin|LED_BLUE_2_Pin
                          |LED_WHITE_2_Pin|LED_WHITE_3_Pin|LED_GREEN_1_Pin|LED_RED_1_Pin
                          |LED_ORANGE_1_Pin|LED_BLUE_1_Pin|LED_WHITE_1_Pin, GPIO_PIN_RESET);

  /*Configure GPIO pin Output Level */
  HAL_GPIO_WritePin(GPIOB, LD1_Pin|SPI_SS3_Pin|SPI_SS4_Pin|LD3_Pin
                          |IMU_SS_Pin|LD2_Pin, GPIO_PIN_RESET);

  /*Configure GPIO pin Output Level */
  HAL_GPIO_WritePin(GPIOE, SPI_SS1_Pin|SPI_SS2_Pin, GPIO_PIN_RESET);

  /*Configure GPIO pin Output Level */
  HAL_GPIO_WritePin(GPIOG, GPIO_PIN_6|MOTOR4_DISABLE_Pin|MOTOR3_DISABLE_Pin, GPIO_PIN_RESET);

  /*Configure GPIO pin Output Level */
  HAL_GPIO_WritePin(GPIOD, MOTOR2_DISABLE_Pin|MOTOR1_DISABLE_Pin, GPIO_PIN_RESET);

  /*Configure GPIO pins : JACK_Pin CONFIG_1_Pin CONFIG_2_Pin CONFIG_3_Pin
                           CONFIG_4_Pin */
  GPIO_InitStruct.Pin = JACK_Pin|CONFIG_1_Pin|CONFIG_2_Pin|CONFIG_3_Pin
                          |CONFIG_4_Pin;
  GPIO_InitStruct.Mode = GPIO_MODE_INPUT;
  GPIO_InitStruct.Pull = GPIO_NOPULL;
  HAL_GPIO_Init(GPIOE, &GPIO_InitStruct);

  /*Configure GPIO pin : USER_Btn_Pin */
  GPIO_InitStruct.Pin = USER_Btn_Pin;
  GPIO_InitStruct.Mode = GPIO_MODE_IT_RISING;
  GPIO_InitStruct.Pull = GPIO_NOPULL;
  HAL_GPIO_Init(USER_Btn_GPIO_Port, &GPIO_InitStruct);

  /*Configure GPIO pins : LED_GREEN_2_Pin LED_RED_2_Pin LED_ORANGE_2_Pin LED_BLUE_2_Pin
                           LED_WHITE_2_Pin LED_WHITE_3_Pin LED_GREEN_1_Pin LED_RED_1_Pin
                           LED_ORANGE_1_Pin LED_BLUE_1_Pin LED_WHITE_1_Pin */
  GPIO_InitStruct.Pin = LED_GREEN_2_Pin|LED_RED_2_Pin|LED_ORANGE_2_Pin|LED_BLUE_2_Pin
                          |LED_WHITE_2_Pin|LED_WHITE_3_Pin|LED_GREEN_1_Pin|LED_RED_1_Pin
                          |LED_ORANGE_1_Pin|LED_BLUE_1_Pin|LED_WHITE_1_Pin;
  GPIO_InitStruct.Mode = GPIO_MODE_OUTPUT_PP;
  GPIO_InitStruct.Pull = GPIO_NOPULL;
  GPIO_InitStruct.Speed = GPIO_SPEED_FREQ_LOW;
  HAL_GPIO_Init(GPIOF, &GPIO_InitStruct);

  /*Configure GPIO pins : SPI_INT1_Pin SPI_INT2_Pin SPI_INT3_Pin SPI_INT4_Pin
                           MOTOR2_INDEX_Pin MOTOR2_FAIL_Pin */
  GPIO_InitStruct.Pin = SPI_INT1_Pin|SPI_INT2_Pin|SPI_INT3_Pin|SPI_INT4_Pin
                          |MOTOR2_INDEX_Pin|MOTOR2_FAIL_Pin;
  GPIO_InitStruct.Mode = GPIO_MODE_INPUT;
  GPIO_InitStruct.Pull = GPIO_NOPULL;
  HAL_GPIO_Init(GPIOC, &GPIO_InitStruct);

  /*Configure GPIO pins : LD1_Pin SPI_SS3_Pin SPI_SS4_Pin LD3_Pin
                           IMU_SS_Pin LD2_Pin */
  GPIO_InitStruct.Pin = LD1_Pin|SPI_SS3_Pin|SPI_SS4_Pin|LD3_Pin
                          |IMU_SS_Pin|LD2_Pin;
  GPIO_InitStruct.Mode = GPIO_MODE_OUTPUT_PP;
  GPIO_InitStruct.Pull = GPIO_NOPULL;
  GPIO_InitStruct.Speed = GPIO_SPEED_FREQ_LOW;
  HAL_GPIO_Init(GPIOB, &GPIO_InitStruct);

  /*Configure GPIO pins : SWITH_1_Pin IMU_INT1_Pin IMU_INT2_Pin */
  GPIO_InitStruct.Pin = SWITH_1_Pin|IMU_INT1_Pin|IMU_INT2_Pin;
  GPIO_InitStruct.Mode = GPIO_MODE_INPUT;
  GPIO_InitStruct.Pull = GPIO_NOPULL;
  HAL_GPIO_Init(GPIOB, &GPIO_InitStruct);

  /*Configure GPIO pins : SWITH_2_Pin SWITH_3_Pin */
  GPIO_InitStruct.Pin = SWITH_2_Pin|SWITH_3_Pin;
  GPIO_InitStruct.Mode = GPIO_MODE_INPUT;
  GPIO_InitStruct.Pull = GPIO_NOPULL;
  HAL_GPIO_Init(GPIOF, &GPIO_InitStruct);

  /*Configure GPIO pins : SPI_SS1_Pin SPI_SS2_Pin */
  GPIO_InitStruct.Pin = SPI_SS1_Pin|SPI_SS2_Pin;
  GPIO_InitStruct.Mode = GPIO_MODE_OUTPUT_PP;
  GPIO_InitStruct.Pull = GPIO_NOPULL;
  GPIO_InitStruct.Speed = GPIO_SPEED_FREQ_LOW;
  HAL_GPIO_Init(GPIOE, &GPIO_InitStruct);

  /*Configure GPIO pins : PG6 MOTOR4_DISABLE_Pin MOTOR3_DISABLE_Pin */
  GPIO_InitStruct.Pin = GPIO_PIN_6|MOTOR4_DISABLE_Pin|MOTOR3_DISABLE_Pin;
  GPIO_InitStruct.Mode = GPIO_MODE_OUTPUT_PP;
  GPIO_InitStruct.Pull = GPIO_NOPULL;
  GPIO_InitStruct.Speed = GPIO_SPEED_FREQ_LOW;
  HAL_GPIO_Init(GPIOG, &GPIO_InitStruct);

  /*Configure GPIO pins : USB_OverCurrent_Pin MOTOR3_INDEX_Pin MOTOR3_FAIL_Pin */
  GPIO_InitStruct.Pin = USB_OverCurrent_Pin|MOTOR3_INDEX_Pin|MOTOR3_FAIL_Pin;
  GPIO_InitStruct.Mode = GPIO_MODE_INPUT;
  GPIO_InitStruct.Pull = GPIO_NOPULL;
  HAL_GPIO_Init(GPIOG, &GPIO_InitStruct);

  /*Configure GPIO pin : MOTOR2_ISENSE_Pin */
  GPIO_InitStruct.Pin = MOTOR2_ISENSE_Pin;
  GPIO_InitStruct.Mode = GPIO_MODE_ANALOG;
  GPIO_InitStruct.Pull = GPIO_NOPULL;
  HAL_GPIO_Init(MOTOR2_ISENSE_GPIO_Port, &GPIO_InitStruct);

  /*Configure GPIO pins : MOTOR2_DISABLE_Pin MOTOR1_DISABLE_Pin */
  GPIO_InitStruct.Pin = MOTOR2_DISABLE_Pin|MOTOR1_DISABLE_Pin;
  GPIO_InitStruct.Mode = GPIO_MODE_OUTPUT_PP;
  GPIO_InitStruct.Pull = GPIO_NOPULL;
  GPIO_InitStruct.Speed = GPIO_SPEED_FREQ_LOW;
  HAL_GPIO_Init(GPIOD, &GPIO_InitStruct);

  /*Configure GPIO pins : MOTOR1_INDEX_Pin MOTOR1_FAIL_Pin MOTOR4_INDEX_Pin MOTOR4_FAIL_Pin */
  GPIO_InitStruct.Pin = MOTOR1_INDEX_Pin|MOTOR1_FAIL_Pin|MOTOR4_INDEX_Pin|MOTOR4_FAIL_Pin;
  GPIO_InitStruct.Mode = GPIO_MODE_INPUT;
  GPIO_InitStruct.Pull = GPIO_NOPULL;
  HAL_GPIO_Init(GPIOD, &GPIO_InitStruct);

  /*Configure GPIO pin : MOTOR1_ISENSE_Pin */
  GPIO_InitStruct.Pin = MOTOR1_ISENSE_Pin;
  GPIO_InitStruct.Mode = GPIO_MODE_ANALOG;
  GPIO_InitStruct.Pull = GPIO_NOPULL;
  HAL_GPIO_Init(MOTOR1_ISENSE_GPIO_Port, &GPIO_InitStruct);

  /*Configure GPIO pins : MOTOR4_ISENSE_Pin MOTOR3_ISENSE_Pin */
  GPIO_InitStruct.Pin = MOTOR4_ISENSE_Pin|MOTOR3_ISENSE_Pin;
  GPIO_InitStruct.Mode = GPIO_MODE_ANALOG;
  GPIO_InitStruct.Pull = GPIO_NOPULL;
  HAL_GPIO_Init(GPIOG, &GPIO_InitStruct);

}

void Error_Handler(void)
{
    __disable_irq();
    while (1)
    {
    }
}
